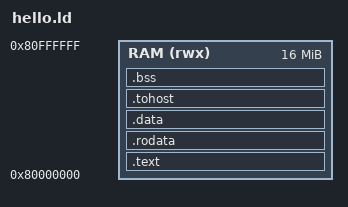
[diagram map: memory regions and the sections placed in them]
/* hello 固件链接脚本（M1.7）：基址 0x80000000，16M RAM，栈顶在 RAM 末尾 */

OUTPUT_ARCH(riscv)
ENTRY(_start)

MEMORY
{
    RAM (rwx) : ORIGIN = 0x80000000, LENGTH = 16M
}

SECTIONS
{
    .text : {
        KEEP(*(.text.init))
        *(.text .text.*)
    } > RAM

    .rodata : ALIGN(4) {
        *(.rodata .rodata.*)
    } > RAM

    .data : ALIGN(4) {
        *(.data .data.*)
    } > RAM

    .tohost : ALIGN(64) {
        *(.tohost)
    } > RAM

    .bss : ALIGN(4) {
        __bss_start = .;
        *(.bss .bss.* COMMON)
        __bss_end = .;
    } > RAM

    . = ALIGN(16);
    _stack_top = ORIGIN(RAM) + LENGTH(RAM);
}
